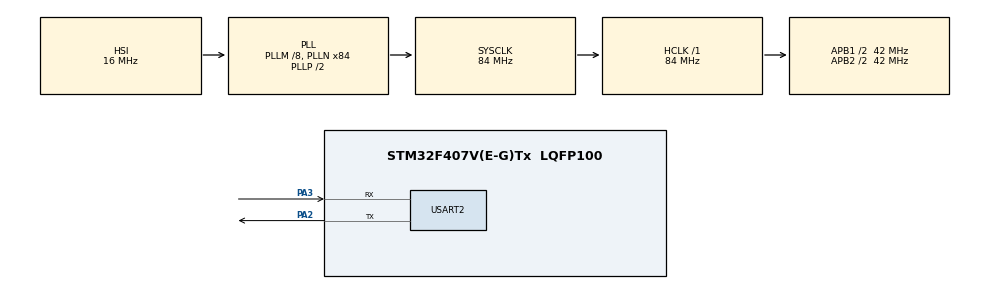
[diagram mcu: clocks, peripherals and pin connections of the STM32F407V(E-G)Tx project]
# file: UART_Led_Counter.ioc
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Dma.Request0=USART2_RX
Dma.USART2_RX.0.Direction=DMA_PERIPH_TO_MEMORY
Dma.USART2_RX.0.FIFOMode=DMA_FIFOMODE_DISABLE
Dma.USART2_RX.0.Instance=DMA1_Stream5
Dma.USART2_RX.0.MemDataAlignment=DMA_MDATAALIGN_BYTE
Dma.USART2_RX.0.MemInc=DMA_MINC_ENABLE
Dma.USART2_RX.0.Mode=DMA_NORMAL
Dma.USART2_RX.0.PeriphDataAlignment=DMA_PDATAALIGN_BYTE
Dma.USART2_RX.0.PeriphInc=DMA_PINC_DISABLE
Dma.USART2_RX.0.Priority=DMA_PRIORITY_LOW
Mcu.Family=STM32F4
Mcu.Name=STM32F407V(E-G)Tx
Mcu.Package=LQFP100
NVIC.DMA1_Stream5_IRQn=true\:0\:0\:false\:false\:true\:false\:true
NVIC.PriorityGroup=NVIC_PRIORITYGROUP_0
PA2.Mode=Asynchronous
PA2.Signal=USART2_TX
PA3.Mode=Asynchronous
PA3.Signal=USART2_RX
ProjectManager.HeapSize=0x200
ProjectManager.StackSize=0x400
ProjectManager.TargetToolchain=STM32CubeIDE
RCC.48MHZClocksFreq_Value=24000000
RCC.AHBFreq_Value=84000000
RCC.APB1CLKDivider=RCC_HCLK_DIV2
RCC.APB1Freq_Value=42000000
RCC.APB1TimFreq_Value=84000000
RCC.APB2CLKDivider=RCC_HCLK_DIV2
RCC.APB2Freq_Value=42000000
RCC.APB2TimFreq_Value=84000000
RCC.CortexFreq_Value=84000000
RCC.HCLKFreq_Value=84000000
RCC.HSE_VALUE=8000000
RCC.HSI_VALUE=16000000
RCC.PLLM=8
RCC.PLLN=84
RCC.PLLQ=7
RCC.SYSCLKFreq_VALUE=84000000
RCC.SYSCLKSource=RCC_SYSCLKSOURCE_PLLCLK
RCC.VCOOutputFreq_Value=168000000
USART2.VirtualMode=VM_ASYNC
board=STM32F407G-DISC1

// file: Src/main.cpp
/* USER CODE BEGIN Header */
/**
  ******************************************************************************
  * @file           : main.c
  * @brief          : Main program body
  ******************************************************************************
  * @attention
  *
  * <h2><center>&copy; Copyright (c) 2021 STMicroelectronics.
  * All rights reserved.</center></h2>
  *
  * This software component is licensed by ST under BSD 3-Clause license,
  * the "License"; You may not use this file except in compliance with the
  * License. You may obtain a copy of the License at:
  *                        opensource.org/licenses/BSD-3-Clause
  *
  ******************************************************************************
  */
/* USER CODE END Header */

#include "main.h"
#include <string.h>
#include <iostream>

using namespace std;

/* USER CODE BEGIN PTD */

/*
External LEDs -> GPIO Port_D  8, 9, 10, 11
*/

#define LED0 11
#define LED1 10
#define LED2 8
#define LED3 9

/* USER CODE END PTD */

UART_HandleTypeDef huart2;
DMA_HandleTypeDef hdma_usart2_rx;

/* USER CODE BEGIN PV */

char rxData[50];
int STOP_COUNT = 0;

/* USER CODE END PV */

void SystemClock_Config(void);
static void MX_GPIO_Init(void);
static void MX_DMA_Init(void);
static void MX_USART2_UART_Init(void);
/* USER CODE BEGIN PFP */

void setPortDOutMode(int pinNum);
void sendPortDOutData(int pinNum, bool highSig);
int getPinNum(int LEDNum);

/* USER CODE END PFP */

/* USER CODE BEGIN 0 */

class Counter
{
public:
  int tot_bits = 4;

private:
  int counterVal = 16;
  string order = "Up";
  int startVal = 0;
  int endVal = counterVal - 1;

  void setStartEndVals()
  {
    if (order == "Down")
    {
      startVal = -counterVal + 1;
      endVal = 0;
    }
    else
    {
      startVal = 0;
      endVal = counterVal - 1;
    }
  }

public:
  Counter() {}

  Counter(int value, string countOrder)
  {
    setCountValue(value);
    setCountOrder(countOrder);
  }

  Counter(int value)
  {
    setCountValue(value);
  }

  void setCountValue(int value)
  {
    counterVal = value;
    setStartEndVals();
  }

  void setCountOrder(string countOrder)
  {
    order = countOrder;
    setStartEndVals();
  }

  void startCounter()
  {
    for (int countVal = startVal; countVal <= endVal; countVal++)
    {
      if (STOP_COUNT)
      {
      	  break;
      }

      int num = countVal;
      if (order == "Down")
      {
        num *= -1;
      }

      char number[30];
      sprintf(number, "%d\r\n", num);
      HAL_UART_Transmit(&huart2, (__uint8_t *)number, strlen(number), 10);
      writeLED(num);
      HAL_Delay(200);
    }
  }

private:
  void writeLED(int num)
  {
    int bitVal, index = 0;
    for (int bitShift = tot_bits - 1; bitShift >= 0; bitShift--, index++)
    {
      bitVal = (num & (1 << bitShift)) >> bitShift;
      sendPortDOutData(getPinNum(bitShift), bitVal);
    }
  }
};

int getPinNum(int LEDNum)
{
  switch (LEDNum)
  {
  case 0:
    return LED0;

  case 1:
    return LED1;

  case 2:
    return LED2;

  default:
    return LED3;
  }
}

void setPortDOutMode(int pinNum)
{
  __uint32_t *pPortDMode = (__uint32_t *)0x40020C00;

  *pPortDMode &= ~(3 << (2 * pinNum));
  *pPortDMode |= (1 << (2 * pinNum));
}

void sendPortDOutData(int pinNum, bool highSig)
{
  __uint32_t *pPortDOut = (__uint32_t *)0x40020C14;

  if (highSig)
  {
    *pPortDOut |= (1 << pinNum);
  }
  else
  {
    *pPortDOut &= ~(1 << pinNum);
  }
}

/* USER CODE END 0 */

int main(void)
{

  /* MCU Configuration--------------------------------------------------------*/

  /* Reset of all peripherals, Initializes the Flash interface and the Systick. */
  HAL_Init();

  /* Configure the system clock */
  SystemClock_Config();

  /* Initialize all configured peripherals */
  MX_GPIO_Init();
  MX_DMA_Init();
  MX_USART2_UART_Init();
  /* USER CODE BEGIN 2 */

	// Connection Success Message
	char txdata[50] = "Connection Successful!\r\n";
	HAL_UART_Transmit(&huart2, (uint8_t*)txdata, strlen(txdata), 10);
	HAL_UART_Receive_DMA(&huart2, (uint8_t* )rxData, 6);

  // Enable clock for bus of GPIOD, i.e, AHB1
  // RCC base -> 40023800 + offset 30
  __uint32_t *pClockControl = (__uint32_t *)0x40023830;
  *pClockControl |= (1 << 3);

  //Port_D Pins Enable
  setPortDOutMode(LED0);
  setPortDOutMode(LED1);
  setPortDOutMode(LED2);
  setPortDOutMode(LED3);
  Counter c1;

  /* USER CODE END 2 */

  /* Infinite loop */
  while (1)
  {

  if (!STOP_COUNT){
      //c1.startCounter();
      c1.startCounter();
    }

  }
}

void SystemClock_Config(void)
{
  RCC_OscInitTypeDef RCC_OscInitStruct = {0};
  RCC_ClkInitTypeDef RCC_ClkInitStruct = {0};

  /** Configure the main internal regulator output voltage
  */
  __HAL_RCC_PWR_CLK_ENABLE();
  __HAL_PWR_VOLTAGESCALING_CONFIG(PWR_REGULATOR_VOLTAGE_SCALE1);
  /** Initializes the RCC Oscillators according to the specified parameters
  * in the RCC_OscInitTypeDef structure.
  */
  RCC_OscInitStruct.OscillatorType = RCC_OSCILLATORTYPE_HSI;
  RCC_OscInitStruct.HSIState = RCC_HSI_ON;
  RCC_OscInitStruct.HSICalibrationValue = RCC_HSICALIBRATION_DEFAULT;
  RCC_OscInitStruct.PLL.PLLState = RCC_PLL_ON;
  RCC_OscInitStruct.PLL.PLLSource = RCC_PLLSOURCE_HSI;
  RCC_OscInitStruct.PLL.PLLM = 8;
  RCC_OscInitStruct.PLL.PLLN = 84;
  RCC_OscInitStruct.PLL.PLLP = RCC_PLLP_DIV2;
  RCC_OscInitStruct.PLL.PLLQ = 7;
  if (HAL_RCC_OscConfig(&RCC_OscInitStruct) != HAL_OK)
  {
    Error_Handler();
  }
  /** Initializes the CPU, AHB and APB buses clocks
  */
  RCC_ClkInitStruct.ClockType = RCC_CLOCKTYPE_HCLK|RCC_CLOCKTYPE_SYSCLK
                              |RCC_CLOCKTYPE_PCLK1|RCC_CLOCKTYPE_PCLK2;
  RCC_ClkInitStruct.SYSCLKSource = RCC_SYSCLKSOURCE_PLLCLK;
  RCC_ClkInitStruct.AHBCLKDivider = RCC_SYSCLK_DIV1;
  RCC_ClkInitStruct.APB1CLKDivider = RCC_HCLK_DIV2;
  RCC_ClkInitStruct.APB2CLKDivider = RCC_HCLK_DIV2;

  if (HAL_RCC_ClockConfig(&RCC_ClkInitStruct, FLASH_LATENCY_2) != HAL_OK)
  {
    Error_Handler();
  }
}

static void MX_USART2_UART_Init(void)
{

  huart2.Instance = USART2;
  huart2.Init.BaudRate = 115200;
  huart2.Init.WordLength = UART_WORDLENGTH_8B;
  huart2.Init.StopBits = UART_STOPBITS_1;
  huart2.Init.Parity = UART_PARITY_NONE;
  huart2.Init.Mode = UART_MODE_TX_RX;
  huart2.Init.HwFlowCtl = UART_HWCONTROL_NONE;
  huart2.Init.OverSampling = UART_OVERSAMPLING_16;
  if (HAL_UART_Init(&huart2) != HAL_OK)
  {
    Error_Handler();
  }

}

static void MX_DMA_Init(void)
{

  /* DMA controller clock enable */
  __HAL_RCC_DMA1_CLK_ENABLE();

  /* DMA interrupt init */
  /* DMA1_Stream5_IRQn interrupt configuration */
  HAL_NVIC_SetPriority(DMA1_Stream5_IRQn, 0, 0);
  HAL_NVIC_EnableIRQ(DMA1_Stream5_IRQn);

}

static void MX_GPIO_Init(void)
{

  /* GPIO Ports Clock Enable */
  __HAL_RCC_GPIOA_CLK_ENABLE();

}

/* USER CODE BEGIN 4 */
void HAL_UART_RxCpltCallback(UART_HandleTypeDef *huart)
{
  /* Prevent unused argument(s) compilation warning */
  UNUSED(huart);
  /* NOTE: This function should not be modified, when the callback is needed,
           the HAL_UART_RxCpltCallback could be implemented in the user file
   */
  char msg[50] = "Message received!\r\n";
  HAL_UART_Transmit(&huart2, (__uint8_t*) msg, strlen(msg), 10);
  HAL_UART_Transmit(&huart2, (__uint8_t*) rxData, strlen(rxData), 10);

  if (strcmp(rxData, "Toggle") == 0)
  {
	  STOP_COUNT ^= 1;
  }
}
/* USER CODE END 4 */

void Error_Handler(void)
{
  __disable_irq();
  while (1)
  {
  }
}

/************************ (C) COPYRIGHT STMicroelectronics *****END OF FILE****/
